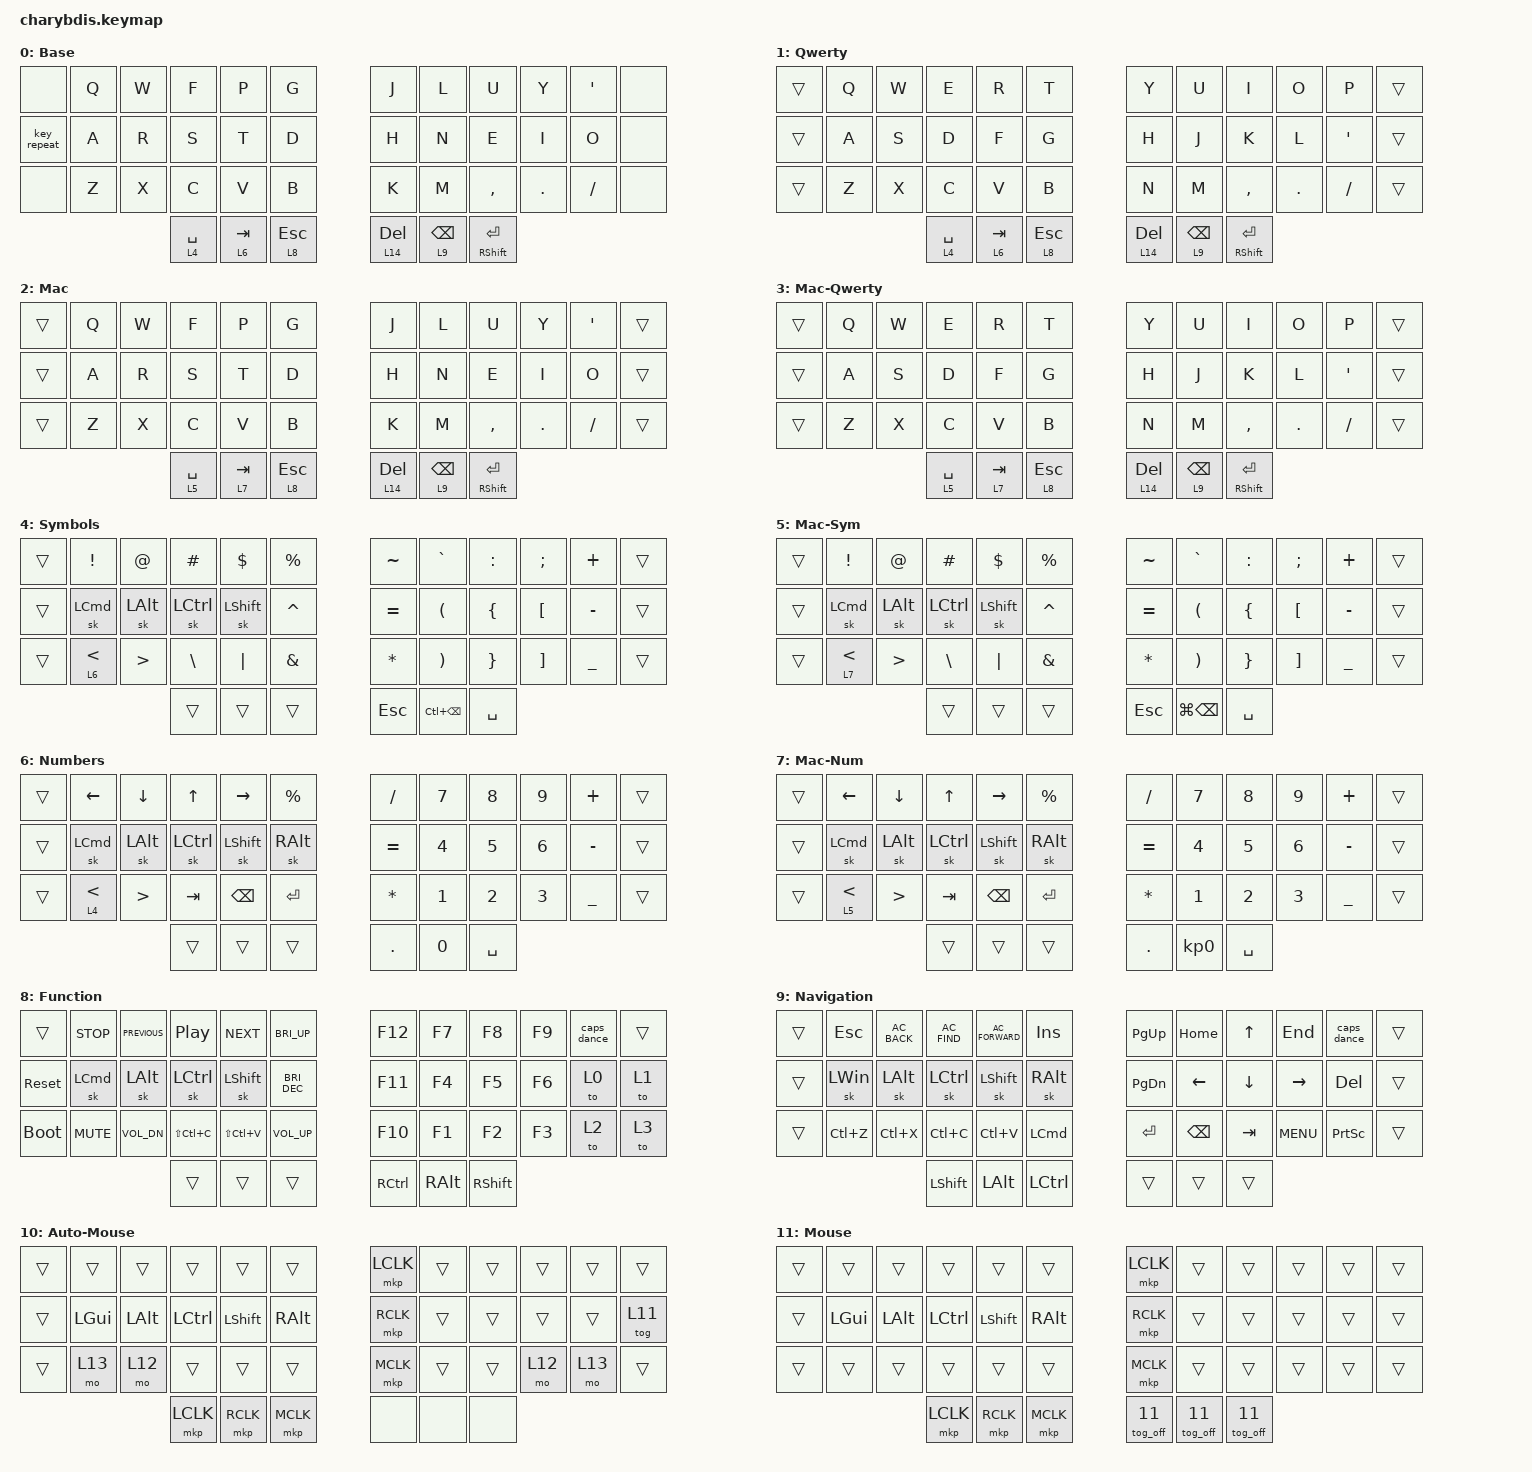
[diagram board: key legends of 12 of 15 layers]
#include <behaviors/mouse_keys.dtsi>
#include <dt-bindings/zmk/mouse.h>
#include <behaviors.dtsi>
#include <dt-bindings/zmk/bt.h>
#include <dt-bindings/zmk/keys.h>
#include <dt-bindings/zmk/outputs.h>
#include <dt-bindings/zmk/pointing.h>

#define U_TAPPING_TERM 200

/ {
    chosen { zmk,matrix_transform = &default_transform; };
};

/ {
    combos {
        compatible = "zmk,combos";

        LeftClickRight {
            bindings = <&mkp LCLK>;
            key-positions = <6 7>;
        };

        RightClickRight {
            bindings = <&mkp RCLK>;
            key-positions = <18 19>;
        };

        MiddleClickRight {
            bindings = <&mkp MCLK>;
            key-positions = <30 31>;
        };

        oe {
            bindings = <&oe>;
            key-positions = <10 22>;
        };

        ue {
            bindings = <&ue>;
            key-positions = <8 20>;
        };

        ae {
            bindings = <&ae>;
            key-positions = <13 1>;
        };

        ss {
            bindings = <&ss>;
            key-positions = <3 15>;
        };
    };

    behaviors {
        ltq: ltq {
            compatible = "zmk,behavior-hold-tap";
            label = "LTQ";
            bindings = <&mo>, <&kp>;

            #binding-cells = <2>;
            tapping-term-ms = <200>;
            quick-tap-ms = <180>;
            flavor = "tap-preferred";
        };

        caps_dance: caps_dance {
            compatible = "zmk,behavior-tap-dance";
            label = "CAPS_DANCE";
            #binding-cells = <0>;
            bindings = <&caps_word>, <&kp CAPS>;
        };

        tog_off: tog_off {
            compatible = "zmk,behavior-toggle-layer";
            label = "TOG_OFF";
            #binding-cells = <1>;
            toggle-mode = "off";
        };

        shift_enter: shift_enter {
            compatible = "zmk,behavior-hold-tap";
            label = "SHIFT_ENTER";
            bindings = <&sk>, <&kp>;

            #binding-cells = <2>;
            tapping-term-ms = <160>;
        };
    };

    macros {
        ae: umlaut_a {
            compatible = "zmk,behavior-macro";
            #binding-cells = <0>;
            bindings = <&kp RA(DOUBLE_QUOTES) &kp A>;
            label = "UMLAUT_A";
        };

        ue: umlaut_u {
            compatible = "zmk,behavior-macro";
            #binding-cells = <0>;
            bindings = <&kp RA(DOUBLE_QUOTES) &kp U>;
            label = "UMLAUT_U";
        };

        oe: oe {
            compatible = "zmk,behavior-macro";
            #binding-cells = <0>;
            bindings = <&kp RA(DOUBLE_QUOTES) &kp O>;
            label = "OE";
        };

        ss: ss {
            compatible = "zmk,behavior-macro";
            #binding-cells = <0>;
            bindings = <&kp RA(S) &kp S>;
            label = "SS";
        };
    };

    keymap {
        compatible = "zmk,keymap";

        Base {
            bindings = <
&none        &kp Q  &kp W  &kp F         &kp P       &kp G                          &kp J             &kp L                      &kp U      &kp Y    &kp SQT   &none
&key_repeat  &kp A  &kp R  &kp S         &kp T       &kp D                          &kp H             &kp N                      &kp E      &kp I    &kp O     &none
&none        &kp Z  &kp X  &kp C         &kp V       &kp B                          &kp K             &kp M                      &kp COMMA  &kp DOT  &kp FSLH  &none
                           &ltq 4 SPACE  &ltq 6 TAB  &ltq 8 ESCAPE  &ltq 14 DELETE  &ltq 9 BACKSPACE  &shift_enter RSHIFT ENTER
            >;
        };

        Qwerty {
            bindings = <
&trans  &kp Q  &kp W  &kp E         &kp R       &kp T                          &kp Y             &kp U                     &kp I      &kp O    &kp P     &trans
&trans  &kp A  &kp S  &kp D         &kp F       &kp G                          &kp H             &kp J                     &kp K      &kp L    &kp SQT   &trans
&trans  &kp Z  &kp X  &kp C         &kp V       &kp B                          &kp N             &kp M                     &kp COMMA  &kp DOT  &kp FSLH  &trans
                      &ltq 4 SPACE  &ltq 6 TAB  &ltq 8 ESCAPE  &ltq 14 DELETE  &ltq 9 BACKSPACE  &shift_enter RSHFT ENTER
            >;
        };

        Mac {
            bindings = <
&trans  &kp Q  &kp W  &kp F         &kp P       &kp G                          &kp J             &kp L                      &kp U      &kp Y    &kp SQT   &trans
&trans  &kp A  &kp R  &kp S         &kp T       &kp D                          &kp H             &kp N                      &kp E      &kp I    &kp O     &trans
&trans  &kp Z  &kp X  &kp C         &kp V       &kp B                          &kp K             &kp M                      &kp COMMA  &kp DOT  &kp FSLH  &trans
                      &ltq 5 SPACE  &ltq 7 TAB  &ltq 8 ESCAPE  &ltq 14 DELETE  &ltq 9 BACKSPACE  &shift_enter RSHIFT ENTER
            >;
        };

        Mac-Qwerty {
            bindings = <
&trans  &kp Q  &kp W  &kp E         &kp R       &kp T                          &kp Y             &kp U                      &kp I      &kp O    &kp P     &trans
&trans  &kp A  &kp S  &kp D         &kp F       &kp G                          &kp H             &kp J                      &kp K      &kp L    &kp SQT   &trans
&trans  &kp Z  &kp X  &kp C         &kp V       &kp B                          &kp N             &kp M                      &kp COMMA  &kp DOT  &kp FSLH  &trans
                      &ltq 5 SPACE  &ltq 7 TAB  &ltq 8 ESCAPE  &ltq 14 DELETE  &ltq 9 BACKSPACE  &shift_enter RSHIFT ENTER
            >;
        };

        Symbols {
            bindings = <
&trans  &kp EXCL          &kp AT            &kp HASH   &kp DLLR   &kp PRCNT               &kp TILDE     &kp GRAVE              &kp COLON        &kp SEMICOLON      &kp PLUS        &trans
&trans  &sk LCMD          &sk LEFT_ALT      &sk LCTRL  &sk LSHFT  &kp CARET               &kp EQUAL     &kp LEFT_PARENTHESIS   &kp LEFT_BRACE   &kp LEFT_BRACKET   &kp MINUS       &trans
&trans  &ltq 6 LESS_THAN  &kp GREATER_THAN  &kp BSLH   &kp PIPE   &kp AMPERSAND           &kp ASTERISK  &kp RIGHT_PARENTHESIS  &kp RIGHT_BRACE  &kp RIGHT_BRACKET  &kp UNDERSCORE  &trans
                                            &trans     &trans     &trans         &kp ESC  &kp LC(BSPC)  &kp SPACE
            >;
        };

        Mac-Sym {
            bindings = <
&trans  &kp EXCL          &kp AT            &kp HASH   &kp DLLR   &kp PRCNT               &kp TILDE     &kp GRAVE              &kp COLON        &kp SEMI  &kp PLUS        &trans
&trans  &sk LCMD          &sk LEFT_ALT      &sk LCTRL  &sk LSHFT  &kp CARET               &kp EQUAL     &kp LEFT_PARENTHESIS   &kp LEFT_BRACE   &kp LBKT  &kp MINUS       &trans
&trans  &ltq 7 LESS_THAN  &kp GREATER_THAN  &kp BSLH   &kp PIPE   &kp AMPERSAND           &kp ASTERISK  &kp RIGHT_PARENTHESIS  &kp RIGHT_BRACE  &kp RBKT  &kp UNDERSCORE  &trans
                                            &trans     &trans     &trans         &kp ESC  &kp LG(BSPC)  &kp SPACE
            >;
        };

        Numbers {
            bindings = <
&trans  &kp LEFT          &kp DOWN          &kp UP     &kp RIGHT  &kp PERCENT                &kp SLASH     &kp N7     &kp N8  &kp N9  &kp PLUS   &trans
&trans  &sk LCMD          &sk LEFT_ALT      &sk LCTRL  &sk LSHFT  &sk RIGHT_ALT              &kp EQUAL     &kp N4     &kp N5  &kp N6  &kp MINUS  &trans
&trans  &ltq 4 LESS_THAN  &kp GREATER_THAN  &kp TAB    &kp BSPC   &kp ENTER                  &kp ASTERISK  &kp N1     &kp N2  &kp N3  &kp UNDER  &trans
                                            &trans     &trans     &trans         &kp PERIOD  &kp N0        &kp SPACE
            >;
        };

        Mac-Num {
            bindings = <
&trans  &kp LEFT          &kp DOWN          &kp UP     &kp RIGHT  &kp PERCENT                &kp SLASH     &kp N7     &kp N8  &kp N9  &kp PLUS   &trans
&trans  &sk LCMD          &sk LEFT_ALT      &sk LCTRL  &sk LSHFT  &sk RIGHT_ALT              &kp EQUAL     &kp N4     &kp N5  &kp N6  &kp MINUS  &trans
&trans  &ltq 5 LESS_THAN  &kp GREATER_THAN  &kp TAB    &kp BSPC   &kp ENTER                  &kp ASTERISK  &kp N1     &kp N2  &kp N3  &kp UNDER  &trans
                                            &trans     &trans     &trans         &kp PERIOD  &kp KP_N0     &kp SPACE
            >;
        };

        Function {
            bindings = <
&trans       &kp C_STOP  &kp C_PREVIOUS  &kp C_PP       &kp C_NEXT     &kp C_BRI_UP              &kp F12        &kp F7     &kp F8  &kp F9  &caps_dance  &trans
&sys_reset   &sk LCMD    &sk LEFT_ALT    &sk LCTRL      &sk LSHFT      &kp C_BRI_DEC             &kp F11        &kp F4     &kp F5  &kp F6  &to 0        &to 1
&bootloader  &kp C_MUTE  &kp C_VOL_DN    &kp LS(LC(C))  &kp LS(LC(V))  &kp C_VOL_UP              &kp F10        &kp F1     &kp F2  &kp F3  &to 2        &to 3
                                         &trans         &trans         &trans         &kp RCTRL  &kp RIGHT_ALT  &kp RSHFT
            >;
        };

        Navigation {
            bindings = <
&trans  &kp ESCAPE  &kp C_AC_BACK  &kp C_AC_FIND  &kp C_AC_FORWARD  &kp INS                &kp PAGE_UP    &kp HOME       &kp UP    &kp END     &caps_dance      &trans
&trans  &sk LWIN    &sk LEFT_ALT   &sk LCTRL      &sk LSHFT         &sk RIGHT_ALT          &kp PAGE_DOWN  &kp LEFT       &kp DOWN  &kp RIGHT   &kp DELETE       &trans
&trans  &kp LC(Z)   &kp LC(X)      &kp LC(C)      &kp LC(V)         &kp LCMD               &kp ENTER      &kp BACKSPACE  &kp TAB   &kp C_MENU  &kp PRINTSCREEN  &trans
                                   &kp LSHIFT     &kp LALT          &kp LCTRL      &trans  &trans         &trans
            >;
        };

        Auto-Mouse {
            bindings = <
&trans  &trans    &trans    &trans     &trans     &trans            &mkp LCLK  &trans  &trans  &trans  &trans  &trans
&trans  &kp LGUI  &kp LALT  &kp LCTRL  &kp LSHFT  &kp RALT          &mkp RCLK  &trans  &trans  &trans  &trans  &tog 11
&trans  &mo 13    &mo 12    &trans     &trans     &trans            &mkp MCLK  &trans  &trans  &mo 12  &mo 13  &trans
                            &mkp LCLK  &mkp RCLK  &mkp MCLK  &none  &none      &none
            >;
        };

        Mouse {
            bindings = <
&trans  &trans    &trans    &trans     &trans     &trans                  &mkp LCLK    &trans       &trans  &trans  &trans  &trans
&trans  &kp LGUI  &kp LALT  &kp LCTRL  &kp LSHFT  &kp RALT                &mkp RCLK    &trans       &trans  &trans  &trans  &trans
&trans  &trans    &trans    &trans     &trans     &trans                  &mkp MCLK    &trans       &trans  &trans  &trans  &trans
                            &mkp LCLK  &mkp RCLK  &mkp MCLK  &tog_off 11  &tog_off 11  &tog_off 11
            >;
        };

        Scroll {
            bindings = <
&trans  &trans  &trans  &trans  &trans  &trans          &trans  &trans  &trans  &trans  &trans  &trans
&trans  &trans  &trans  &trans  &trans  &trans          &trans  &trans  &trans  &trans  &trans  &trans
&trans  &trans  &trans  &trans  &trans  &trans          &trans  &trans  &trans  &trans  &trans  &trans
                        &trans  &trans  &trans  &trans  &trans  &trans
            >;
        };

        Snipe {
            bindings = <
&trans  &trans  &trans  &trans  &trans  &trans          &trans  &trans  &trans  &trans  &trans  &trans
&trans  &trans  &trans  &trans  &trans  &trans          &trans  &trans  &trans  &trans  &trans  &trans
&trans  &trans  &trans  &trans  &trans  &trans          &trans  &trans  &trans  &trans  &trans  &trans
                        &trans  &trans  &trans  &trans  &trans  &trans
            >;
        };

        Control {
            bindings = <
&none        &none  &none  &none   &none   &none           &bt BT_SEL 0  &bt BT_SEL 1  &bt BT_SEL 2  &bt BT_SEL 3  &bt BT_SEL 4  &none
&sys_reset   &none  &none  &none   &none   &none           &out OUT_TOG  &bt BT_CLR    &none         &none         &none         &sys_reset
&bootloader  &none  &none  &none   &none   &none           &out OUT_BLE  &out OUT_USB  &none         &none         &none         &bootloader
                           &trans  &trans  &trans  &trans  &trans        &trans
            >;
        };
    };
};
